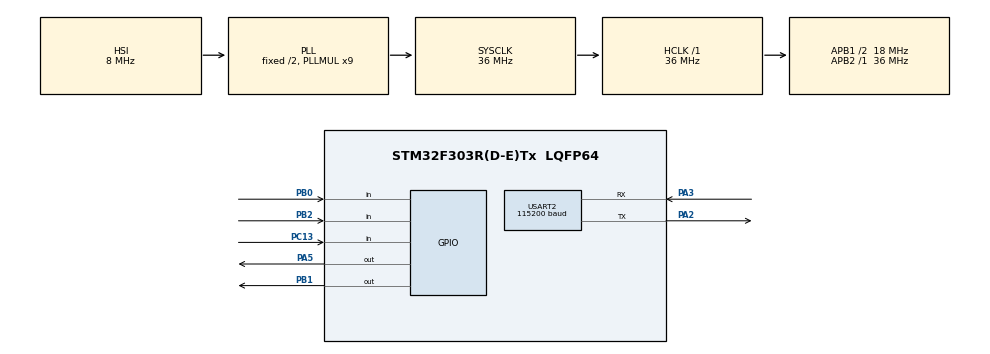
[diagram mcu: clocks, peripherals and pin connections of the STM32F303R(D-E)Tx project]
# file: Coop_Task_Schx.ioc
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Mcu.Family=STM32F3
Mcu.Name=STM32F303R(D-E)Tx
Mcu.Package=LQFP64
NVIC.PriorityGroup=NVIC_PRIORITYGROUP_4
NVIC.TIM2_IRQn=true\:0\:0\:false\:false\:true\:true\:true\:true
NVIC.USART2_IRQn=true\:0\:0\:false\:false\:true\:true\:true\:true
PA13.Mode=Serial_Wire
PA13.Signal=SYS_JTMS-SWDIO
PA14.Mode=Serial_Wire
PA14.Signal=SYS_JTCK-SWCLK
PA2.Mode=Asynchronous
PA2.Signal=USART2_TX
PA3.Mode=Asynchronous
PA3.Signal=USART2_RX
PA5.Signal=GPIO_Output
PB0.Signal=GPIO_Input
PB1.Signal=GPIO_Output
PB2.Signal=GPIO_Input
PC13.Signal=GPIO_Input
ProjectManager.HeapSize=0x200
ProjectManager.StackSize=0x400
ProjectManager.TargetToolchain=STM32CubeIDE
RCC.AHBFreq_Value=36000000
RCC.APB1CLKDivider=RCC_HCLK_DIV2
RCC.APB1Freq_Value=18000000
RCC.APB1TimFreq_Value=36000000
RCC.APB2Freq_Value=36000000
RCC.APB2TimFreq_Value=36000000
RCC.CortexFreq_Value=36000000
RCC.HCLKFreq_Value=36000000
RCC.HSE_VALUE=8000000
RCC.HSI_VALUE=8000000
RCC.LSE_VALUE=32768
RCC.PLLMUL=RCC_PLL_MUL9
RCC.SYSCLKFreq_VALUE=36000000
RCC.SYSCLKSourceVirtual=RCC_SYSCLKSOURCE_PLLCLK
RCC.USBFreq_Value=36000000
TIM2.AutoReloadPreload=TIM_AUTORELOAD_PRELOAD_ENABLE
TIM2.Period=0xFFFF
TIM2.Prescaler=71
USART2.BaudRate=115200
USART2.VirtualMode-Asynchronous=VM_ASYNC
VP_TIM2_VS_ClockSourceINT.Mode=Internal
board=custom

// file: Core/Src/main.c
/* USER CODE BEGIN Header */
/**
  ******************************************************************************
  * @file           : main.c
  * @brief          : Main program body
  ******************************************************************************
  * @attention
  *
  * Copyright (c) 2025 STMicroelectronics.
  * All rights reserved.
  *
  * This software is licensed under terms that can be found in the LICENSE file
  * in the root directory of this software component.
  * If no LICENSE file comes with this software, it is provided AS-IS.
  *
  ******************************************************************************
  */
/* USER CODE END Header */
#include "main.h"

/* USER CODE BEGIN Includes */
#include "task.h"
#include "DHT11.h"

/* USER CODE END Includes */

TIM_HandleTypeDef htim2;

UART_HandleTypeDef huart2;

void SystemClock_Config(void);
static void MX_GPIO_Init(void);
static void MX_TIM2_Init(void);
static void MX_USART2_UART_Init(void);
/* USER CODE BEGIN PFP */
void flying_fish_ir_task(void);
/* USER CODE END PFP */

/* USER CODE BEGIN 0 */
dht11_t dht11;
/* USER CODE END 0 */

int main(void)
{

  /* MCU Configuration--------------------------------------------------------*/

  /* Reset of all peripherals, Initializes the Flash interface and the Systick. */
  HAL_Init();

  /* USER CODE BEGIN Init */
  init_dht11(&dht11, &htim2, GPIOB, GPIO_PIN_0);
  HAL_TIM_Base_Start(&htim2);

  /* USER CODE END Init */

  /* Configure the system clock */
  SystemClock_Config();

  /* USER CODE BEGIN SysInit */

      scheduler_init();
      //scheduler_add(log_telemetry, 10000);
      //scheduler_add(check_health, 2000);
      scheduler_add(thermal_mon, 3000);
      scheduler_add(ir_sensor_task, 1000);
      //scheduler_add(commn_link_mon, 40000);
      //scheduler_add(handle_command, 50000);

  /* USER CODE END SysInit */

  /* Initialize all configured peripherals */
  MX_GPIO_Init();
  MX_TIM2_Init();
  MX_USART2_UART_Init();

  /* Infinite loop */
  while (1)
  {
	  scheduler_run();
  }
}

void SystemClock_Config(void)
{
  RCC_OscInitTypeDef RCC_OscInitStruct = {0};
  RCC_ClkInitTypeDef RCC_ClkInitStruct = {0};
  RCC_PeriphCLKInitTypeDef PeriphClkInit = {0};

  /** Initializes the RCC Oscillators according to the specified parameters
  * in the RCC_OscInitTypeDef structure.
  */
  RCC_OscInitStruct.OscillatorType = RCC_OSCILLATORTYPE_HSI;
  RCC_OscInitStruct.HSIState = RCC_HSI_ON;
  RCC_OscInitStruct.HSICalibrationValue = RCC_HSICALIBRATION_DEFAULT;
  RCC_OscInitStruct.PLL.PLLState = RCC_PLL_ON;
  RCC_OscInitStruct.PLL.PLLSource = RCC_PLLSOURCE_HSI;
  RCC_OscInitStruct.PLL.PLLMUL = RCC_PLL_MUL9;
  RCC_OscInitStruct.PLL.PREDIV = RCC_PREDIV_DIV1;
  if (HAL_RCC_OscConfig(&RCC_OscInitStruct) != HAL_OK)
  {
    Error_Handler();
  }

  /** Initializes the CPU, AHB and APB buses clocks
  */
  RCC_ClkInitStruct.ClockType = RCC_CLOCKTYPE_HCLK|RCC_CLOCKTYPE_SYSCLK
                              |RCC_CLOCKTYPE_PCLK1|RCC_CLOCKTYPE_PCLK2;
  RCC_ClkInitStruct.SYSCLKSource = RCC_SYSCLKSOURCE_PLLCLK;
  RCC_ClkInitStruct.AHBCLKDivider = RCC_SYSCLK_DIV1;
  RCC_ClkInitStruct.APB1CLKDivider = RCC_HCLK_DIV2;
  RCC_ClkInitStruct.APB2CLKDivider = RCC_HCLK_DIV1;

  if (HAL_RCC_ClockConfig(&RCC_ClkInitStruct, FLASH_LATENCY_1) != HAL_OK)
  {
    Error_Handler();
  }
  PeriphClkInit.PeriphClockSelection = RCC_PERIPHCLK_USART2|RCC_PERIPHCLK_TIM2;
  PeriphClkInit.Usart2ClockSelection = RCC_USART2CLKSOURCE_PCLK1;
  PeriphClkInit.Tim2ClockSelection = RCC_TIM2CLK_HCLK;
  if (HAL_RCCEx_PeriphCLKConfig(&PeriphClkInit) != HAL_OK)
  {
    Error_Handler();
  }
}

static void MX_TIM2_Init(void)
{

  TIM_ClockConfigTypeDef sClockSourceConfig = {0};
  TIM_MasterConfigTypeDef sMasterConfig = {0};

  htim2.Instance = TIM2;
  htim2.Init.Prescaler = 71;
  htim2.Init.CounterMode = TIM_COUNTERMODE_UP;
  htim2.Init.Period = 0xFFFF;
  htim2.Init.ClockDivision = TIM_CLOCKDIVISION_DIV1;
  htim2.Init.AutoReloadPreload = TIM_AUTORELOAD_PRELOAD_ENABLE;
  if (HAL_TIM_Base_Init(&htim2) != HAL_OK)
  {
    Error_Handler();
  }
  sClockSourceConfig.ClockSource = TIM_CLOCKSOURCE_INTERNAL;
  if (HAL_TIM_ConfigClockSource(&htim2, &sClockSourceConfig) != HAL_OK)
  {
    Error_Handler();
  }
  sMasterConfig.MasterOutputTrigger = TIM_TRGO_RESET;
  sMasterConfig.MasterSlaveMode = TIM_MASTERSLAVEMODE_DISABLE;
  if (HAL_TIMEx_MasterConfigSynchronization(&htim2, &sMasterConfig) != HAL_OK)
  {
    Error_Handler();
  }

}

static void MX_USART2_UART_Init(void)
{

  huart2.Instance = USART2;
  huart2.Init.BaudRate = 115200;
  huart2.Init.WordLength = UART_WORDLENGTH_8B;
  huart2.Init.StopBits = UART_STOPBITS_1;
  huart2.Init.Parity = UART_PARITY_NONE;
  huart2.Init.Mode = UART_MODE_TX_RX;
  huart2.Init.HwFlowCtl = UART_HWCONTROL_NONE;
  huart2.Init.OverSampling = UART_OVERSAMPLING_16;
  huart2.Init.OneBitSampling = UART_ONE_BIT_SAMPLE_DISABLE;
  huart2.AdvancedInit.AdvFeatureInit = UART_ADVFEATURE_NO_INIT;
  if (HAL_UART_Init(&huart2) != HAL_OK)
  {
    Error_Handler();
  }

}

static void MX_GPIO_Init(void)
{
  GPIO_InitTypeDef GPIO_InitStruct = {0};

  /* GPIO Ports Clock Enable */
  __HAL_RCC_GPIOC_CLK_ENABLE();
  __HAL_RCC_GPIOA_CLK_ENABLE();
  __HAL_RCC_GPIOB_CLK_ENABLE();

  /*Configure GPIO pin Output Level */
  HAL_GPIO_WritePin(GPIOA, GPIO_PIN_5, GPIO_PIN_RESET);

  /*Configure GPIO pin Output Level */
  HAL_GPIO_WritePin(GPIOB, GPIO_PIN_0|GPIO_PIN_1, GPIO_PIN_RESET);

  /*Configure GPIO pin : PC13 */
  GPIO_InitStruct.Pin = GPIO_PIN_13;
  GPIO_InitStruct.Mode = GPIO_MODE_INPUT;
  GPIO_InitStruct.Pull = GPIO_NOPULL;
  HAL_GPIO_Init(GPIOC, &GPIO_InitStruct);

  /*Configure GPIO pin : PA5 */
  GPIO_InitStruct.Pin = GPIO_PIN_5;
  GPIO_InitStruct.Mode = GPIO_MODE_OUTPUT_PP;
  GPIO_InitStruct.Pull = GPIO_NOPULL;
  GPIO_InitStruct.Speed = GPIO_SPEED_FREQ_LOW;
  HAL_GPIO_Init(GPIOA, &GPIO_InitStruct);

  /*Configure GPIO pins : PB0 PB1 */
  GPIO_InitStruct.Pin = GPIO_PIN_0;
  GPIO_InitStruct.Mode = GPIO_MODE_INPUT;
  GPIO_InitStruct.Pull = GPIO_PULLDOWN; // or GPIO_PULLUP if needed
  HAL_GPIO_Init(GPIOB, &GPIO_InitStruct);

  // Keep PB1 as output if still needed
  GPIO_InitStruct.Pin = GPIO_PIN_1;
  GPIO_InitStruct.Mode = GPIO_MODE_OUTPUT_PP;
  GPIO_InitStruct.Pull = GPIO_NOPULL;
  GPIO_InitStruct.Speed = GPIO_SPEED_FREQ_LOW;
  HAL_GPIO_Init(GPIOB, &GPIO_InitStruct);

  /*Configure GPIO pin : PB2 */
  GPIO_InitStruct.Pin = GPIO_PIN_2;
  GPIO_InitStruct.Mode = GPIO_MODE_INPUT;
  GPIO_InitStruct.Pull = GPIO_PULLDOWN;
  HAL_GPIO_Init(GPIOB, &GPIO_InitStruct);

}

void Error_Handler(void)
{
  __disable_irq();
  while (1)
  {
  }
}
